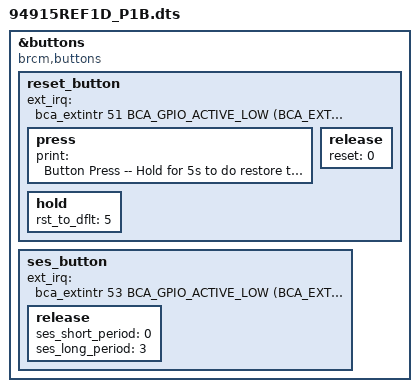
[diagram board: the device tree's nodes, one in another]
#include "94915REF1D.dts"

&buttons {
		compatible = "brcm,buttons";
		/* reset button fixed in the P1B rev board */
		reset_button {
			ext_irq = <&bca_extintr 51 BCA_GPIO_ACTIVE_LOW (BCA_EXTINTR_TYPE_LOW_LEVEL | BCA_EXTINTR_TYPE_SENSE_EDGE)>;
			press {
				print = "Button Press -- Hold for 5s to do restore to default";
			};
			hold {
				rst_to_dflt = <5>;
			};
			release {
				reset = <0>;
			};	
		};
		ses_button {
			ext_irq = <&bca_extintr 53 BCA_GPIO_ACTIVE_LOW (BCA_EXTINTR_TYPE_LOW_LEVEL | BCA_EXTINTR_TYPE_SENSE_EDGE)>;
			release {
				ses_short_period = <0>;
				ses_long_period = <3>;
			};
		};		
};

